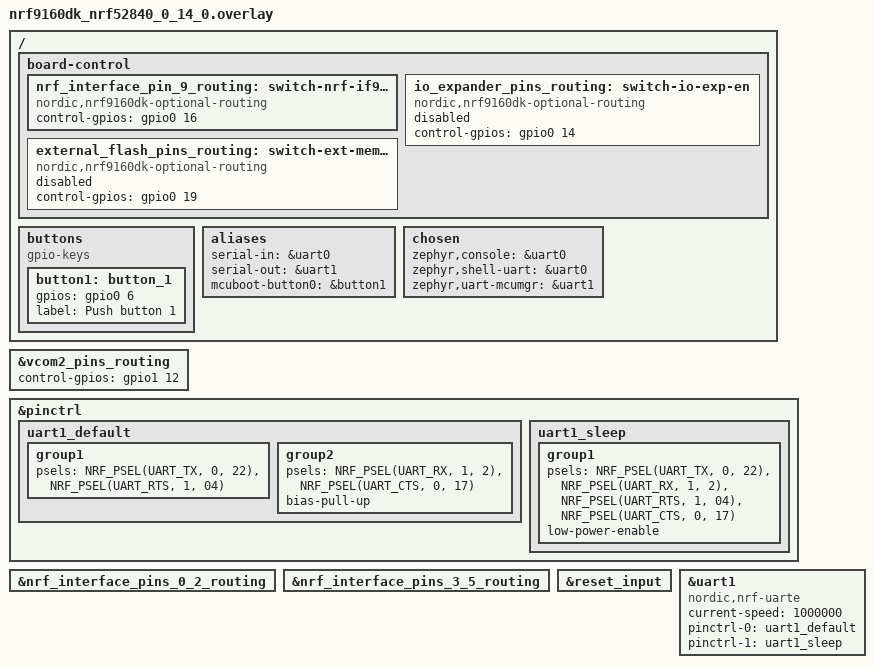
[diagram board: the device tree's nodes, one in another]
/*
 * Copyright (c) 2021 Nordic Semiconductor ASA
 *
 * SPDX-License-Identifier: Apache-2.0
 */

 / {
	board-control {
		nrf_interface_pin_9_routing: switch-nrf-if9-ctrl {
			compatible = "nordic,nrf9160dk-optional-routing";
			control-gpios = <&gpio0 16 GPIO_ACTIVE_HIGH>;
			status = "okay";
		};

		io_expander_pins_routing: switch-io-exp-en {
			compatible = "nordic,nrf9160dk-optional-routing";
			control-gpios = <&gpio0 14 GPIO_ACTIVE_HIGH>;
			status = "disabled";
		};

		external_flash_pins_routing: switch-ext-mem-ctrl {
			compatible = "nordic,nrf9160dk-optional-routing";
			control-gpios = <&gpio0 19 GPIO_ACTIVE_HIGH>;
			status = "disabled";
		};
	};
};

&vcom2_pins_routing {
	/* No need to drive P0.12 together with P1.12 in this board revision. */
	control-gpios = <&gpio1 12 GPIO_ACTIVE_HIGH>;
};

&pinctrl {
	uart1_default: uart1_default {
		group1 {
			psels = <NRF_PSEL(UART_TX, 0, 22)>,
				<NRF_PSEL(UART_RTS, 1, 04)>;
		};
		group2 {
			psels = <NRF_PSEL(UART_RX, 1, 2)>,
				<NRF_PSEL(UART_CTS, 0, 17)>;
			bias-pull-up;
		};
	};

	uart1_sleep: uart1_sleep {
		group1 {
			psels =<NRF_PSEL(UART_TX, 0, 22)>,
				<NRF_PSEL(UART_RX, 1, 2)>,
				<NRF_PSEL(UART_RTS, 1, 04)>,
				<NRF_PSEL(UART_CTS, 0, 17)>;
			low-power-enable;
		};
	};

};

&nrf_interface_pins_0_2_routing {
        status = "okay";
};

&nrf_interface_pins_3_5_routing {
        status = "okay";
};

&reset_input {
	status = "okay";
};

&uart1 {
	compatible = "nordic,nrf-uarte";
	current-speed = <1000000>;
	status = "okay";
	pinctrl-0 = <&uart1_default>;
	pinctrl-1 = <&uart1_sleep>;
	pinctrl-names = "default", "sleep";
};



/ {
	buttons {
		compatible = "gpio-keys";
		button1: button_1 {
			gpios = <&gpio0 6 (GPIO_PULL_DOWN | GPIO_ACTIVE_HIGH)>;
			label = "Push button 1";
		};
	};

	aliases {
		serial-in = &uart0;
		serial-out = &uart1;
		mcuboot-button0 = &button1;
	};
};

/ {
        chosen {
                zephyr,console = &uart0;
                zephyr,shell-uart = &uart0;
                zephyr,uart-mcumgr = &uart1;
        };
};
